# FM33A0XXX register map
File version: 1.0
ARM 32-bit Cortex SC000 + MPU Microcontroller based device
CPU: SC000 r1p0, little endian, MPU, no FPU, 3 interrupt priority bits
Registers are 32-bit, read-write, reset 0x0 unless marked. A register's access mark holds for its fields unless they carry their own. Offsets are from the block's base; lines under a group give offsets from that group; [hi:lo] are bit positions; {n}, {i} and the like mark numbered series; 'fields as' and 'values as' point back to an identical list; <NAME> marks a mode.

## Memory map
0x40000000 SCU size 0x100 — System config unit
0x40000100 PMU size 0x100 — POWER MANAGEMENT UNIT
0x40000200 RCC size 0x200 — RESET AND CLOCK CONTROL UNIT
0x40000400 DMA size 0x200 — Peripheral DMA, Direct Memory Access
0x40000800 HSPI size 0x40 — High speed SPI
0x40000840 SPI1 size 0x40 — SPI Serial Peripheral Interface
0x40000880 SPI2 size 0x40
0x40000C00 GPIOA size 0x20 — GPIO PORTA
0x40000C20 GPIOB size 0x20
0x40000C40 GPIOC size 0x20
0x40000C60 GPIOD size 0x20
0x40000C80 GPIOE size 0x20
0x40000CA0 GPIOF size 0x20
0x40000CC0 GPIOG size 0x20
0x40000CE0 GPIO_COMMON size 0x40 — GPIO_COMMON Registers
0x40001000 NVMIF size 0x40 — NVMIF Registers
0x40010000 CRC size 0x40
0x40010C00 DISP size 0x100 — DISP Registers
0x40011000 RTC size 0x100 — RTC Registers
0x40011400 IWDT size 0x40
0x40011800 WWDT size 0x40 — WWDT Registers
0x40011C00 U7816_0 size 0x2C — U7816_0 Registers
0x40011C2C U7816_1 size 0x2C
0x40012000 UART_COMMON size 0xC — UART_COMMON Registers
0x4001200C UART0 size 0x20 — UART0 Registers
0x4001202C UART1 size 0x20
0x4001204C UART2 size 0x20
0x4001206C UART3 size 0x20
0x4001208C UART4 size 0x20
0x400120AC UART5 size 0x20
0x40012400 I2C size 0x40 — I2C Registers
0x40012800 ANAC size 0x80 — ANAC Registers
0x40012C00 RAMBIST size 0x40 — RAMBIST REGISTERS
0x40013000 BTIMER1 size 0x44 — BASIC TIMER1 Registers
0x40013044 BTIMER2 size 0x44
0x40013090 ETIMER1 size 0x20 — EXTENDED TIMER Registers
0x400130B0 ETIMER2 size 0x20
0x400130D0 ETIMER3 size 0x20
0x400130F0 ETIMER4 size 0x20
0x40013400 LPTIM size 0x20 — LPTIM Registers
0x40013800 AES size 0x80 — AES Registers
0x40013C04 TRNG size 0x20 — TRNG Registers

## Interrupts
0 WWDT (RCC, WWDT)
1 SVD (ANAC)
2 RTC
3 NVMIF
4 FDET (ANAC)
5 ADC (ANAC)
6 HSPI
7 SPI1
8 SPI2
9 UART0
10 UART1
11 UART2
12 UART3
13 UART4
14 UART5
15 U7816_0
16 U7816_1
17 I2C
18 DISP
19 AES
20 LPTIM
21 DMA
22 TRNG (ANAC, TRNG)
23 COMP (ANAC)
24 BTIMER1
25 BTIMER2
26 ETIMER1
27 ETIMER2
28 ETIMER3
29 ETIMER4
30 GPIO (GPIO_COMMON)

## SCU — System config unit
Base 0x40000000
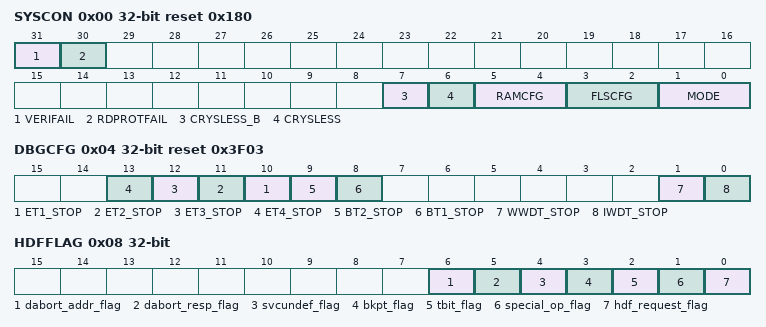
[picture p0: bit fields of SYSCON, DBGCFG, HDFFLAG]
0x00 SYSCON ro reset 0x180 — System Config Register
  [31] VERIFAIL — VERIFY FAIL
    0=PASS (NVR1 verify pass); 1=FAIL (NVR1 verify pass)
  [30] RDPROTFAIL — NVR0 Validation fail
    0=PASS (NVR0 Validation pass); 1=FAIL (NVR0 Validation fail)
  [7] CRYSLESS_B — toggle of CRYSLESS Bit
    0=CRYSTLESS (crystal and FDET is not available); 1=CRYSL (CRYSTAL and FDET is available)
  [6] CRYSLESS — CRYSLESS config
    0=CRYSTL (crystal is available); 1=CRYSLESS (CRYSTAL and FDET is not available)
  [5:4] RAMCFG — RAM Config
    0=64KB (RAM size is 64KB); 1=48KB (RAM size is 48KB); 2=32KB (RAM size is 32KB); 3=16KB (RAM size is 16KB)
  [3:2] FLSCFG — Flash Config
    0=512KB (Flash size is 512K); 1=384KB (Flash size is 384K); 2=256KB (Flash size is 256K); 3=192KB (Flash size is 192K)
  [1:0] MODE — chip work mode
    0=user mode; 1=Manufacture mode; 2=user mode; 3=Original mode
0x04 DBGCFG reset 0x3F03 — debug congfig, only use at bebug mode
  [n+9] ET{n}_STOP (n=1..4) — set ET{n} stop at debug
    0=RUNNING (ET{n} is running); 1=STOPPED (ET{n} is not running)
  [9] BT2_STOP — set BT2 stop at debug
    0=RUNNING (BT2 is running); 1=STOPPED (BT2 is not running)
  [8] BT1_STOP — set BT1 stop at debug
    0=RUNNING (BT1 is running); 1=STOPPED (BT1 is not running)
  [1] WWDT_STOP — SET WWDT STOP AT DEBUG
    0=RUNNING (wwdt is running); 1=STOPPED (wwdt is not running)
  [0] IWDT_STOP — SET IWDT STOP AT DEBUG
    0=RUNNING (iwdt is running); 1=STOPPED (iwdt is not running)
0x08 HDFFLAG — Hard Fault Flag
  [6] dabort_addr_flag — access adress is not alignment,write 1 to clear
    0=legal_access (no operation is address unalignment); 1=ilegal_access (some operation is address unalignment)
  [5] dabort_resp_flag — ilegal access to some address, write 1 to clear
    0=legal_access (all access is legal address); 1=ilegal_access (some access is ilegal address)
  [4] svcundef_flag — special operation is implimented
  [3] bkpt_flag — BKPT operation is implimented, Write 1 to clear
    0=NOBKPT (no BKPT operation is implimented); 1=BKPTONCE (at least one BKPT operation is implimented)
  [2] tbit_flag — Thumb-State flag, write 1 to clear
    0=Thumb-State (at Thumb-State); 1=ARM_State (At ARM state)
  [1] special_op_flag — special operation is implimented
    0=NOREQ (no special operation fault is rquested); 1=REQ (Special operation fault is rquested)
  [0] hdf_request_flag — any hard fault is request
    0=NOREQ (no hard fault is rquested); 1=REQ (some hard fault is requested)
